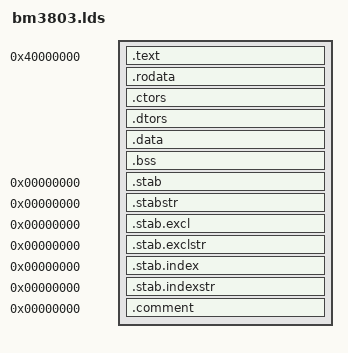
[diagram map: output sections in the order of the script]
OUTPUT_ARCH(sparc)
SECTIONS
{
    . = 0x40000000;

    __text_start = .;
    .text :
    {
        *(.vectors)
        *(.text)
        *(.text.*)

        /* section information for finsh shell */
        . = ALIGN(4);
        __fsymtab_start = .;
        KEEP(*(FSymTab))
        __fsymtab_end = .;
        . = ALIGN(4);
        __vsymtab_start = .;
        KEEP(*(VSymTab))
        __vsymtab_end = .;
        . = ALIGN(4);

        /* section information for modules */
        . = ALIGN(4);
        __rtmsymtab_start = .;
        KEEP(*(RTMSymTab))
        __rtmsymtab_end = .;

        /* section information for initialization */
        . = ALIGN(4);
        __rt_init_start = .;
        KEEP(*(SORT(.rti_fn*)))
        __rt_init_end = .;
    } =0
    __text_end = .;

    __rodata_start = .;
    .rodata   : { *(.rodata) *(.rodata.*) }
    __rodata_end = .;

    . = ALIGN(4);
    .ctors :
    {
        PROVIDE(__ctors_start__ = .);
        KEEP(*(SORT(.ctors.*)))
        KEEP(*(.ctors))
        PROVIDE(__ctors_end__ = .);
    }

    .dtors :
    {
        PROVIDE(__dtors_start__ = .);
        KEEP(*(SORT(.dtors.*)))
        KEEP(*(.dtors))
        PROVIDE(__dtors_end__ = .);
    }

    . = ALIGN(8);
    __data_start = .;
    .data :
    {
        *(.data)
        *(.data.*)
    }
    __data_end = .;

    . = ALIGN(8);
    __bss_start = .;
    .bss       :
    {
    *(.bss)
    *(.bss.*)
    *(COMMON)
    . = ALIGN(4);
    }
    . = ALIGN(4);
    __bss_end = .;

    /* Stabs debugging sections.  */
    .stab 0 : { *(.stab) }
    .stabstr 0 : { *(.stabstr) }
    .stab.excl 0 : { *(.stab.excl) }
    .stab.exclstr 0 : { *(.stab.exclstr) }
    .stab.index 0 : { *(.stab.index) }
    .stab.indexstr 0 : { *(.stab.indexstr) }
    .comment 0 : { *(.comment) }

    _end = .;
}
